# ADC12 register map
Vendor: Texas Instruments
Peripheral module from a debugger description file (folder UCD3138R032RSM).
Registers are 12-bit, read-only, no defined reset value unless marked. A register's access mark holds for its fields unless they carry their own. Offsets are as the file gives them; lines under a group give offsets from that group; [hi:lo] are bit positions; {n}, {i} and the like mark numbered series; 'fields as' and 'values as' point back to an identical list; <NAME> marks a mode.

## ADC12 — GPADC12_MMR
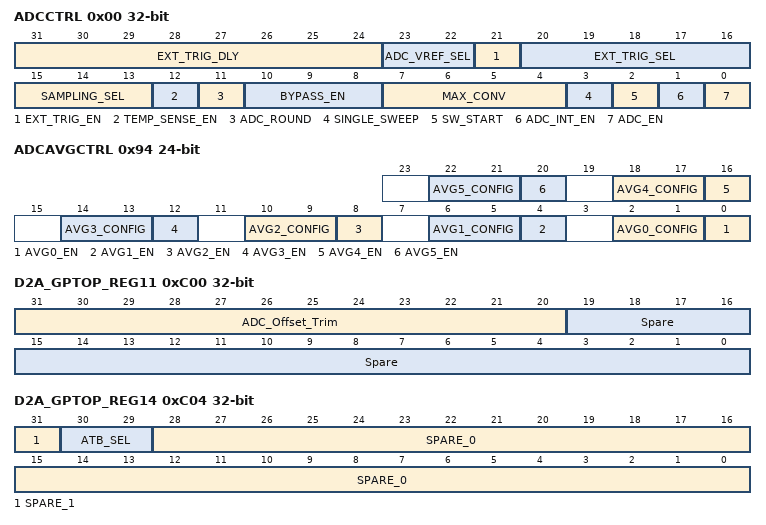
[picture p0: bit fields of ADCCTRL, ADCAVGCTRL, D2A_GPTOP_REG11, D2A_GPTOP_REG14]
0x00 ADCCTRL 32-bit rw — ADC Control Register
  [31:24] EXT_TRIG_DLY — 8-bit External ADC Trigger Delay configuration
  [23:22] ADC_VREF_SEL — ADC Voltage Reference Select
    3=ADC_3p3_Internal_Vref_Selected; 2=ADC_2p5_Internal_Vref_Selected; 1=ADC_External_Vref_Selected_1; 0=ADC_External_Vref_Selected_0
  [21] EXT_TRIG_EN — External Trigger Enable
    1=Enable_External_Trigger_capability; 0=Disable_External_Trigger_capability
  [20:16] EXT_TRIG_SEL — Selects which external trigger can start a conversion loop.
    {v}=DPWM_{v-16}_Sample_Trigger (v=16..19); 15=Analog_Comparator_G_Output; 14=Analog_Comparator_F_Output; 13=Analog_Comparator_E_Output; 12=Analog_Comparator_D_Output; 11=Analog_Comparator_C_Output; 10=Analog_Comparator_B_Output; 9=Analog_Comparator_A_Output; 8=ADC_EXT_TRIG_pin; 7=HS_Loop4_Event_3_DPWMB_Low_Resolution_Edge; 6=HS_Loop4_Event_1_DPWMA_Low_Resolution_Edge; 5=HS_Loop3_Event_3_DPWMB_Low_Resolution_Edge; 4=HS_Loop3_Event_1_DPWMA_Low_Resolution_Edge; 3=HS_Loop2_Event_3_DPWMB_Low_Resolution_Edge; 2=HS_Loop2_Event_1_DPWMA_Low_Resolution_Edge; 1=HS_Loop1_Event_3_DPWMB_Low_Resolution_Edge; 0=HS_Loop1_Event_1_DPWMA_Low_Resolution_Edge
  [15:13] SAMPLING_SEL — Defines ADC sampling and hold timing setup
    7=_0p61MSPS; 6=_0p78MSPS; 5=_1MSPS; 4=_1p28MSPS; 3=_1p56MSPS; 2=_2MSPS; 1=_2p63MSPS; 0=_2p94MSPS_0
  [12] TEMP_SENSE_EN — Temp Sensor Enable
    1=Enable_Temp_Sensor; 0=Disables_Temp_Sensor
  [11] ADC_ROUND — Enables rounding of ADC Result to 10 bits
    1=ADC_Results_are_rounded_to_10_most_significant_bits; 0=ADC_Results_are_not_rounded
  [10:8] BYPASS_EN — Enables dual sample/hold for specific channels.
    7=Dual_SampleHold_Disabled; 6=Dual_SampleHold_enabling_on_Channel_0; 5=Dual_SampleHold_enabling_on_Channel_1; 3=Dual_SampleHold_enabling_on_Channel_2; 0=Dual_SampleHold_enabling_on_Channel_3
  [7:4] MAX_CONV — Maximum number of conversion done in one conversion loop
    15=All_16_conversion_selections_converted_in_the_loop; 0=_1_conversion_selection_converted_in_the_loop
  [3] SINGLE_SWEEP — ADC Conversion Mode
    1=Single_conversion_loop_run; 0=Continuous_conversion_loop_runs
  [2] SW_START — Firmware ADC Conversion Start
    1=Initiate_an_ADC_conversion_loop; 0=Conversions_not_initiated_by_firmware
  [1] ADC_INT_EN — End-of-conversion Interrupt Enable
    1=Enable_End-of-Conversion_Interrupt; 0=Disable_End-of-Conversion_Interrupt
  [0] ADC_EN — ADC12 Enable Control
    1=Enables_ADC; 0=Disables_ADC
0x04 ADCSTAT 7-bit — ADC Status Register
  [6:3] CURRENT_CH
  [2] ADC_EXT_TRIG_VAL
    1=ADC_EXT_TRIG_pin_driven_high; 0=ADC_EXT_TRIG_pin_driven_low
  [1] ADC_INT_RAW — End-of-conversion interrupt flag - raw version
    1=End-of-conversion_interrupt_found; 0=No_End-of-conversion_interrupt_detected
  [0] ADC_INT — End-of-conversion interrupt flag - latched version
    values as ADC_INT_RAW
0x08 ADCTSTCTRL 10-bit access not given — ADC Test Control Register
  [9:6] ADC_TEST_CHAN — ADC Test Channel Select
  [1] ADC_SH_BUFFER_EN — ADC Test S-H Buffer Enable
    1=Enables_ADC_Sample_and_Hold_Buffer; 0=Disable_ADC_Sample_and_Hold_Buffer
  [0] ADC_TEST_EN ro — ADC Test Enable
0x0C ADCSEQSEL0 29-bit access not given — ADC Sequence Select Register 0
  [8n+4] SEQ{n}_SH (n=0..3) — Dual channel sequence select
    1=Dual_sample_Enabled; 0=Dual_Sample_Disabled
  [27:24] SEQ3 — Channel to be converted fourth
  [19:16] SEQ2 — Channel to be converted third
  [11:8] SEQ1 — Channel to be converted second
  [3:0] SEQ0 — Channel to be converted first
0x10 ADCSEQSEL1 29-bit access not given — ADC Sequence Select Register 1
  [8n-28] SEQ{n}_SH (n=4..7) — Dual channel sequence select
    1=Dual_sample_Enabled; 0=Dual_Sample_Disabled
  [27:24] SEQ7 — Channel to be converted eighth
  [19:16] SEQ6 — Channel to be converted seventh
  [11:8] SEQ5 — Channel to be converted sixth
  [3:0] SEQ4 — Channel to be converted fifth
0x14 ADCSEQSEL2 29-bit access not given — ADC Sequence Select Register 2
  fields as ADCSEQSEL0
0x18 ADCSEQSEL3 29-bit access not given — ADC Sequence Select Register 3
  fields as ADCSEQSEL0
{0x1C+4i} ADCRESULT{i} (i=0..15) — ADC Result Register {i}
  [11:0] RESULT
{0x5C+4i} ADCAVGRESULT{i} (i=0..5) — ADC Averaged Result Register {i}
  [11:0] RESULT — First 6 ADC Results have an averaged result
{0x74+4i} ADCCOMPLIM{i} 28-bit access per field (i=0..5) — ADC Digital Compare Limits Register {i}
  [27:16] UPPER_LIMIT rw — Configures the Upper Limit Value to Compare
  [11:0] LOWER_LIMIT rw — Configures the Lower Limit Value to Compare
0x8C ADCCOMPEN 28-bit access per field — ADC Digital Compare Enable Register
  [2n+17] COMP{n}_UP_INT_EN rw (n=0..5) — Dig Comp {n} Upper Limit Interrupt Enable
    1=Interrupt_generation_enabled_on_result_above_upper_limit; 0=Interrupt_generation_disabled_on_result_above_upper_limit
  [2n+16] COMP{n}_LO_INT_EN rw (n=0..5) — Dig Comp {n} Lower Limit Interrupt Enable
    1=Interrupt_generation_enabled_on_result_below_lower_limit; 0=Interrupt_generation_disabled_on_result_below_lower_limit
  [n+8] COMP{n}_DATA_SEL rw (n=0..5) — Digital Comparator {n} Select
    1=Averaged_ADC_Result_Used; 0=Raw_ADC_Result_Used
  [n] COMP{n}_EN rw (n=0..5) — Digital Comparator {n} Enabled
    0=Comp{n}_Disabled; 1=Comp{n}_Enabled
0x90 ADCCOMPRESULT 28-bit — ADC Digital Compare Results Register
  [all] fields
    1=Limit_exceeded; 0=Limit_not_exceeded
  [2n+17] DCOMP{n}_UP_RAW (n=0..5) — Digital Comparator {n} Upper Limit Raw Result
  [2n+16] DCOMP{n}_LO_RAW (n=0..5) — Digital Comparator {n} Lower Limit Raw Result
  [2n+1] DCOMP{n}_UP_INT (n=0..5) — Digital Comparator {n} Upper Limit Interrupt Result-cleared on read
  [2n] DCOMP{n}_LO_INT (n=0..5) — Digital Comparator {n} Lower Limit Interrupt Result-cleared on read
0x94 ADCAVGCTRL 24-bit access per field — ADC Averaging Control Register
  [4n+2:4n+1] AVG{n}_CONFIG rw (n=0..5) — ADC Averaging Module {n} Configuration
    3=Moving_average_of_32_samples; 2=Moving_average_of_16_samples; 1=Moving_average_of_8_samples; 0=Moving_average_of_4_samples
  [4n] AVG{n}_EN rw (n=0..5) — ADC Averaging Module {n} Enable
    1=ADC_Averaging_Enabled; 0=ADC_Averaging_Disabled
0xC00 D2A_GPTOP_REG11 32-bit rw — gptop_reg11_lowv
  [31:20] ADC_Offset_Trim — ADC Offset Trim (Unused)
  [19:0] Spare — Analog Spare Registers
0xC04 D2A_GPTOP_REG14 32-bit rw — gptop_reg14_lowv
  [31] SPARE_1 — Analog Spare Registers
  [30:29] ATB_SEL — ATB Select Lines
  [28:0] SPARE_0 — Analog Spare Registers
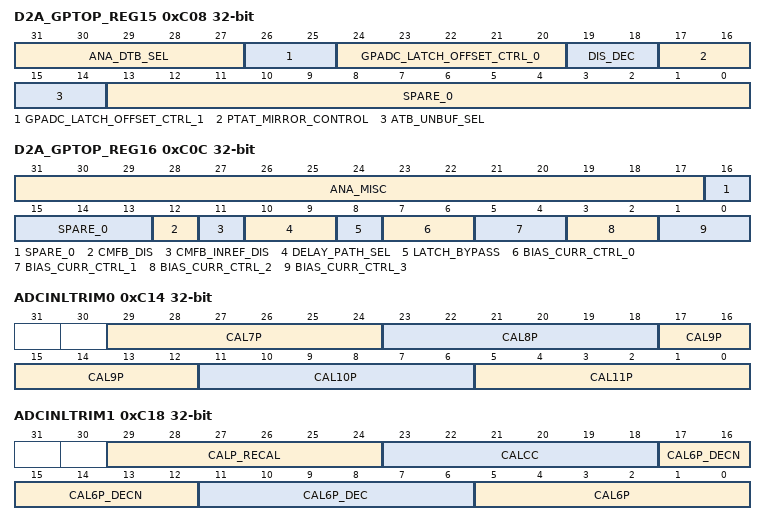
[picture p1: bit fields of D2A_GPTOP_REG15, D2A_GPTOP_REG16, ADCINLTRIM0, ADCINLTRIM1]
0xC08 D2A_GPTOP_REG15 32-bit rw — gptop_reg15_lowv
  [31:27] ANA_DTB_SEL — Analog DTB Select Lines
  [26:25] GPADC_LATCH_OFFSET_CTRL_1 — GPADC Latch Offset Control - EN for p-side/n-side branches
  [24:20] GPADC_LATCH_OFFSET_CTRL_0 — GPADC Latch Offset Control - Offset Control Bits
  [19:18] DIS_DEC — Disable Decision Error Correction Cycles
  [17:16] PTAT_MIRROR_CONTROL — Increase/decrease the mirroring ratios of the PTAT_MIRROR_CONTROL currents going into Pre-amp
  [15:14] ATB_UNBUF_SEL — ATB Unbuffered Select
  [13:0] SPARE_0 — Analog Spare Registers
0xC0C D2A_GPTOP_REG16 32-bit rw — gptop_reg16_lowv
  [31:17] ANA_MISC — Miscellaneous Analog Registers for GPADC
  [16:13] SPARE_0 — Analog Spare Registers
  [12] CMFB_DIS — CMFB Block Disable
  [11] CMFB_INREF_DIS — CMFB Input Ref Disable
  [10:9] DELAY_PATH_SEL — Select Delay Path for MAIN_LATCH & MAIN_RESET
  [8] LATCH_BYPASS
  [7:6] BIAS_CURR_CTRL_0 — ADC Bias Current Control for CM Buffer
  [5:4] BIAS_CURR_CTRL_1 — ADC Bias Current Control for Pre_Amp Stage 1
  [3:2] BIAS_CURR_CTRL_2 — ADC Bias Current Control for Pre_Amp Stage 2
  [1:0] BIAS_CURR_CTRL_3 — ADC Bias Current Control for Pre_Amp Stage 3
0xC10 D2A_GPTOP_REG17 32-bit rw — gptop_reg17_lowv
  [31:0] SPARE — Analog Spare Registers
0xC14 ADCINLTRIM0 32-bit rw — ADC INL Trim Register 0
  [71-6n:66-6n] CAL{n}P (n=7..11) — INL Trim for cal{n}p
0xC18 ADCINLTRIM1 32-bit rw — ADC INL Trim Register 1
  [29:24] CALP_RECAL — INL Trim for calp_recal
  [23:18] CALCC — INL Trim for calCC
  [17:12] CAL6P_DECN — INL Trim for cal6p_decn
  [11:6] CAL6P_DEC — INL Trim for cal6p_dec
  [5:0] CAL6P — INL Trim for cal6p
0xC1C ADCINLTRIMEN 32-bit rw — ADC INL Trim Enable Register
  [0] INL_TRIM_ENABLE — INL Trim Enable Bit
    0=Disable_ADC_INL_Trim_Updates; 1=Enable_ADC_INL_Trim_Updates
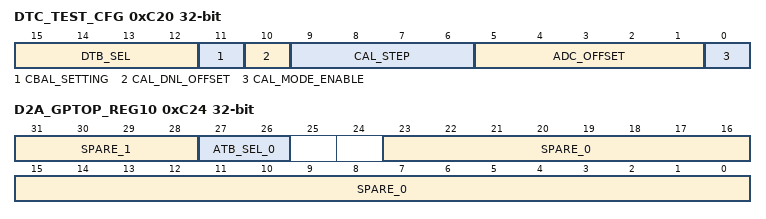
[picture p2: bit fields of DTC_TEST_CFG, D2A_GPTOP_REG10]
0xC20 DTC_TEST_CFG 32-bit rw — DTC Test Config Register
  [15:12] DTB_SEL — Digital DTB Select for GPADC
    6=DCOMP_RDY; 5=CALN_P_O; 4=CALP_O; 3=Analog_Misc; 2=Dual_Sample_Bits; 1=DEC_Bits; 0=ADC_Clocks
  [11] CBAL_SETTING — cbal_setting_i for DTC
  [10] CAL_DNL_OFFSET — cal_dnl_offset_i for DTC
  [9:6] CAL_STEP — cal_step_i for DTC
  [5:1] ADC_OFFSET — adc_offset_i for DTC
  [0] CAL_MODE_ENABLE — cal_mode_enable_i for DTC
0xC24 D2A_GPTOP_REG10 32-bit rw — gptop_reg10_lowv
  [31:28] SPARE_1 — ATB select signal for gptop
  [27:26] ATB_SEL_0 — ATB select bits for sampling buffer
  [23:0] SPARE_0 — Spare Registers
